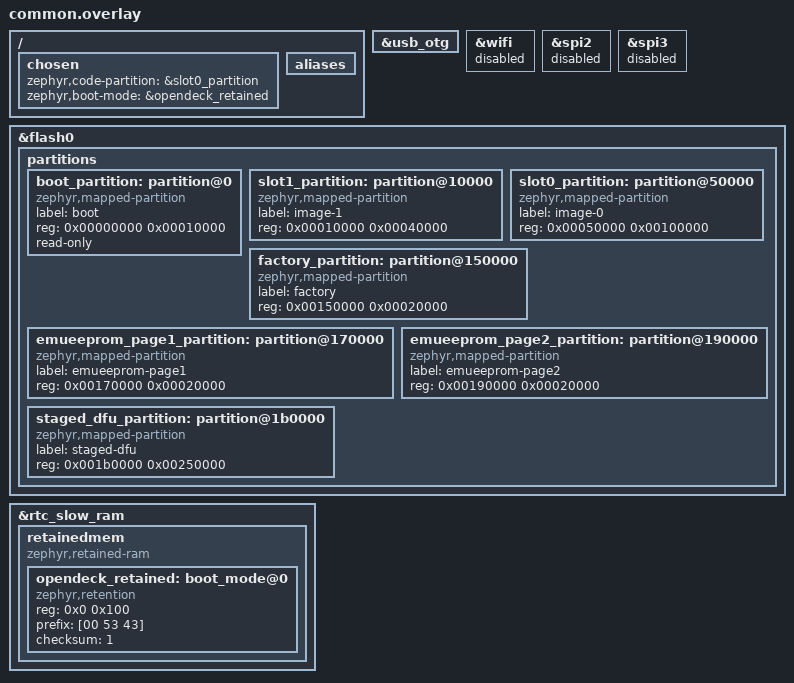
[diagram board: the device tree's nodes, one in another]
/ {
    chosen {
        /delete-property/ zephyr,canbus;
    };

    aliases {
        /delete-property/ led0;
        /delete-property/ led-strip;
        /delete-property/ sdhc0;
    };
};

&usb_otg {
    status = "okay";
};

&wifi {
    status = "disabled";
};

&spi2 {
    status = "disabled";
};

&spi3 {
    status = "disabled";
};

&flash0 {
    /delete-node/ partitions;

    partitions {
        #address-cells = <1>;
        #size-cells = <1>;

        boot_partition: partition@0 {
            compatible = "zephyr,mapped-partition";
            label = "boot";
            reg = <0x00000000 0x00010000>;
            read-only;
        };

        /*
         * image-1 is the OpenDeck bootloader; keep it before image-0 so merged images stay compact.
         * ESP32 mapped application images must start on 64 KiB boundaries.
         */
        slot1_partition: partition@10000 {
            compatible = "zephyr,mapped-partition";
            label = "image-1";
            reg = <0x00010000 0x00040000>;
        };

        slot0_partition: partition@50000 {
            compatible = "zephyr,mapped-partition";
            label = "image-0";
            reg = <0x00050000 0x00100000>;
        };

        factory_partition: partition@150000 {
            compatible = "zephyr,mapped-partition";
            label = "factory";
            reg = <0x00150000 0x00020000>;
        };

        emueeprom_page1_partition: partition@170000 {
            compatible = "zephyr,mapped-partition";
            label = "emueeprom-page1";
            reg = <0x00170000 0x00020000>;
        };

        emueeprom_page2_partition: partition@190000 {
            compatible = "zephyr,mapped-partition";
            label = "emueeprom-page2";
            reg = <0x00190000 0x00020000>;
        };

        staged_dfu_partition: partition@1b0000 {
            compatible = "zephyr,mapped-partition";
            label = "staged-dfu";
            reg = <0x001b0000 0x00250000>;
        };
    };
};

/ {
    chosen {
        zephyr,code-partition = &slot0_partition;
        zephyr,boot-mode = &opendeck_retained;
    };
};

&rtc_slow_ram {
    status = "okay";
    #address-cells = <1>;
    #size-cells = <1>;

    retainedmem {
        compatible = "zephyr,retained-ram";
        status = "okay";
        #address-cells = <1>;
        #size-cells = <1>;

        opendeck_retained: boot_mode@0 {
            compatible = "zephyr,retention";
            status = "okay";
            reg = <0x0 0x100>;
            prefix = [00 53 43];
            checksum = <1>;
        };
    };
};
